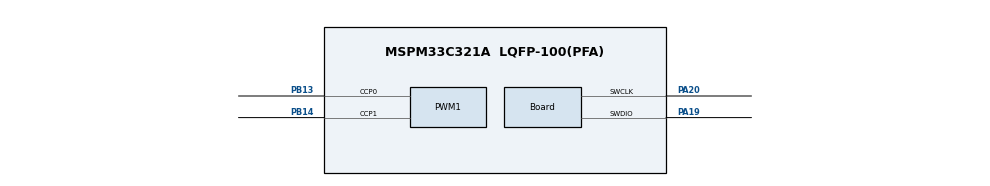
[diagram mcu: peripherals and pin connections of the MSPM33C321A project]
//@cliArgs --device "MSPM33C321A" --package "LQFP-100(PFA)" --part "Default"
//@v2CliArgs --device "MSPM33C321A" --package "LQFP-100(PFA)"
// @cliArgs --board /ti/boards/LP_MSPM33C321A --rtos nortos


/**
 * Import the modules used in this configuration.
 */
const PWM    = scripting.addModule("/ti/driverlib/PWM", {}, false);
const PWM1   = PWM.addInstance();
const SYSCTL = scripting.addModule("/ti/driverlib/SYSCTL");


/**
 * Write custom configuration values to the imported modules.
 */
PWM1.$name                      = "PWM_0";
PWM1.timerCount                 = 512000;
PWM1.peripheral.$assign         = "TIMG12_0";
PWM1.peripheral.ccp0Pin.$assign = "PB13";
PWM1.peripheral.ccp1Pin.$assign = "PB14";
PWM1.PWM_CHANNEL_0.$name        = "ti_driverlib_pwm_PWMTimerCC0";
PWM1.PWM_CHANNEL_0.dutyCycle    = 75;
PWM1.PWM_CHANNEL_1.$name        = "ti_driverlib_pwm_PWMTimerCC1";
PWM1.PWM_CHANNEL_1.dutyCycle    = 50;
PWM1.ccp0PinConfig.$name        = "ti_driverlib_gpio_GPIOPinGeneric0";
PWM1.ccp1PinConfig.$name        = "ti_driverlib_gpio_GPIOPinGeneric1";

const Board                       = scripting.addModule("/ti/driverlib/Board", {}, false);
Board.peripheral.$assign          = "DEBUGSS";
Board.peripheral.swclkPin.$assign = "PA20";
Board.peripheral.swdioPin.$assign = "PA19";

SYSCTL.forceDefaultClkConfig = true;
SYSCTL.peripheral.$assign    = "SYSCTL";

const ProjectConfig              = scripting.addModule("/ti/project_config/ProjectConfig", {}, false);
ProjectConfig.migrationCondition = true;

ProjectConfig.genLinker  = true;
ProjectConfig.genStartup = true;
ProjectConfig.genOpts    = true;
ProjectConfig.genLibs    = true;
